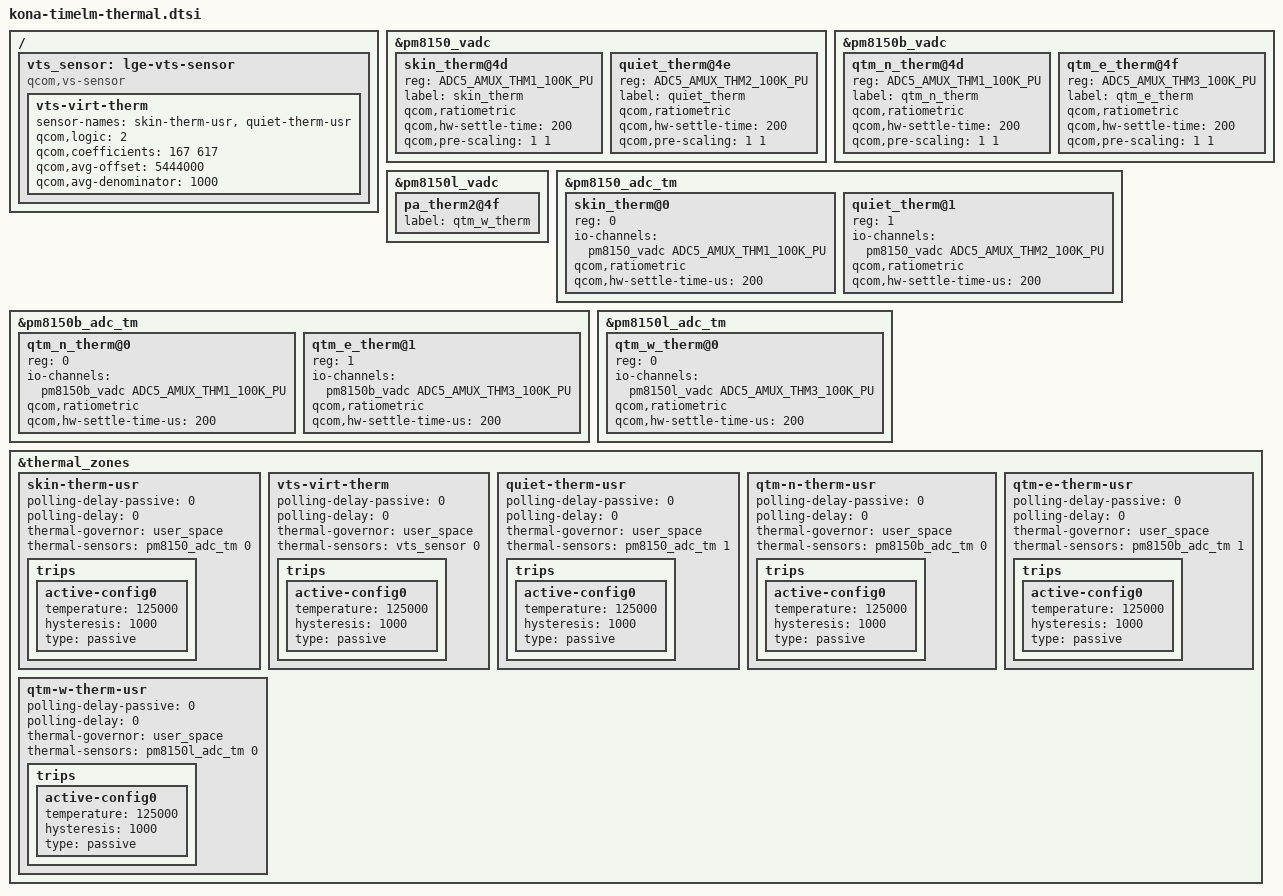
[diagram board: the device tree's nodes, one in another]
// SPDX-License-Identifier: GPL-2.0-only
/*
 * LG V60 ThinQ (timelm) board thermistors.
 *
 * Channel map from the stock LG 4.19 DT (v60-live.dts): every thermistor is
 * a 100K pull-up AMUX input, ratiometric, 200 us settle, 1:1 pre-scaling.
 *
 *   pm8150  (SID 0) AMUX_THM1 0x4d  skin_therm   (board, not the case)
 *   pm8150  (SID 0) AMUX_THM2 0x4e  quiet_therm
 *   pm8150b (SID 2) AMUX_THM1 0x4d  qtm_n_therm  (QTM525 mmW module, north)
 *   pm8150b (SID 2) AMUX_THM3 0x4f  qtm_e_therm  (QTM525 mmW module, east)
 *   pm8150l (SID 4) AMUX_THM3 0x4f  qtm_w_therm  (QTM525 mmW module, west)
 *
 * Each ADC-TM5 child "reg" is the TM channel (0..7); the thermal zone refers
 * to that number.  A sensor binds to the first zone that references it
 * (thermal_of.c), so every channel feeds exactly one zone.
 *
 * Zone names, governor and the single 125 C placeholder trip are stock.
 * skin_therm is a board thermistor that reads several degrees above the
 * case, so it is not a skin temperature.  As on stock, the case temperature
 * is the virtual sensor "vts-virt-therm" (LG lge_virtual_sensor.c, sub6
 * SKUs): 0.167 * skin-therm-usr + 0.617 * quiet-therm-usr + 5.444 C.
 * No cooling maps: these are reported to userspace only, kernel mitigation
 * stays on the tsens zones.
 */

/ {
	vts_sensor: lge-vts-sensor {
		compatible = "qcom,vs-sensor";
		#thermal-sensor-cells = <1>;

		vts-virt-therm {
			sensor-names = "skin-therm-usr", "quiet-therm-usr";
			qcom,logic = <2>;		/* VIRT_WEIGHTED_AVG */
			qcom,coefficients = <167 617>;
			qcom,avg-offset = <5444000>;
			qcom,avg-denominator = <1000>;
		};
	};
};

/* VADC channels */
&pm8150_vadc {
	skin_therm@4d {
		reg = <ADC5_AMUX_THM1_100K_PU>;
		label = "skin_therm";
		qcom,ratiometric;
		qcom,hw-settle-time = <200>;
		qcom,pre-scaling = <1 1>;
	};

	quiet_therm@4e {
		reg = <ADC5_AMUX_THM2_100K_PU>;
		label = "quiet_therm";
		qcom,ratiometric;
		qcom,hw-settle-time = <200>;
		qcom,pre-scaling = <1 1>;
	};
};

&pm8150b_vadc {
	qtm_n_therm@4d {
		reg = <ADC5_AMUX_THM1_100K_PU>;
		label = "qtm_n_therm";
		qcom,ratiometric;
		qcom,hw-settle-time = <200>;
		qcom,pre-scaling = <1 1>;
	};

	qtm_e_therm@4f {
		reg = <ADC5_AMUX_THM3_100K_PU>;
		label = "qtm_e_therm";
		qcom,ratiometric;
		qcom,hw-settle-time = <200>;
		qcom,pre-scaling = <1 1>;
	};
};

&pm8150l_vadc {
	/* QC MTP reference channels, not wired on timelm */
	/delete-node/ camera_flash_therm@4d;
	/delete-node/ skin_msm_therm@4e;

	pa_therm2@4f {
		label = "qtm_w_therm";
	};
};

/* ADC-TM5 channels (thresholds for the thermal zones) */
&pm8150_adc_tm {
	/delete-property/ io-channels;

	skin_therm@0 {
		reg = <0>;
		io-channels = <&pm8150_vadc ADC5_AMUX_THM1_100K_PU>;
		qcom,ratiometric;
		qcom,hw-settle-time-us = <200>;
	};

	quiet_therm@1 {
		reg = <1>;
		io-channels = <&pm8150_vadc ADC5_AMUX_THM2_100K_PU>;
		qcom,ratiometric;
		qcom,hw-settle-time-us = <200>;
	};
};

&pm8150b_adc_tm {
	qtm_n_therm@0 {
		reg = <0>;
		io-channels = <&pm8150b_vadc ADC5_AMUX_THM1_100K_PU>;
		qcom,ratiometric;
		qcom,hw-settle-time-us = <200>;
	};

	qtm_e_therm@1 {
		reg = <1>;
		io-channels = <&pm8150b_vadc ADC5_AMUX_THM3_100K_PU>;
		qcom,ratiometric;
		qcom,hw-settle-time-us = <200>;
	};
};

&pm8150l_adc_tm {
	/delete-property/ io-channels;

	qtm_w_therm@0 {
		reg = <0>;
		io-channels = <&pm8150l_vadc ADC5_AMUX_THM3_100K_PU>;
		qcom,ratiometric;
		qcom,hw-settle-time-us = <200>;
	};
};

&thermal_zones {
	skin-therm-usr {
		polling-delay-passive = <0>;
		polling-delay = <0>;
		thermal-governor = "user_space";
		thermal-sensors = <&pm8150_adc_tm 0>;

		trips {
			active-config0 {
				temperature = <125000>;
				hysteresis = <1000>;
				type = "passive";
			};
		};
	};

	vts-virt-therm {
		polling-delay-passive = <0>;
		polling-delay = <0>;
		thermal-governor = "user_space";
		thermal-sensors = <&vts_sensor 0>;

		trips {
			active-config0 {
				temperature = <125000>;
				hysteresis = <1000>;
				type = "passive";
			};
		};
	};

	quiet-therm-usr {
		polling-delay-passive = <0>;
		polling-delay = <0>;
		thermal-governor = "user_space";
		thermal-sensors = <&pm8150_adc_tm 1>;

		trips {
			active-config0 {
				temperature = <125000>;
				hysteresis = <1000>;
				type = "passive";
			};
		};
	};

	qtm-n-therm-usr {
		polling-delay-passive = <0>;
		polling-delay = <0>;
		thermal-governor = "user_space";
		thermal-sensors = <&pm8150b_adc_tm 0>;

		trips {
			active-config0 {
				temperature = <125000>;
				hysteresis = <1000>;
				type = "passive";
			};
		};
	};

	qtm-e-therm-usr {
		polling-delay-passive = <0>;
		polling-delay = <0>;
		thermal-governor = "user_space";
		thermal-sensors = <&pm8150b_adc_tm 1>;

		trips {
			active-config0 {
				temperature = <125000>;
				hysteresis = <1000>;
				type = "passive";
			};
		};
	};

	qtm-w-therm-usr {
		polling-delay-passive = <0>;
		polling-delay = <0>;
		thermal-governor = "user_space";
		thermal-sensors = <&pm8150l_adc_tm 0>;

		trips {
			active-config0 {
				temperature = <125000>;
				hysteresis = <1000>;
				type = "passive";
			};
		};
	};
};
